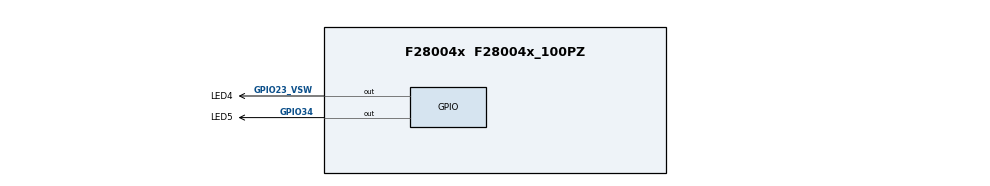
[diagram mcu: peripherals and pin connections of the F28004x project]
/**
 * @cliArgs --device "F28004x" --part "F28004x_100PZ" --package "F28004x_100PZ" --context "system" --product "C2000WARE@26.01.00.00"
 * @versions {"tool":"1.27.0+4565"}
 */

/**
 * Import the modules used in this configuration.
 */
const gpio  = scripting.addModule("/driverlib/gpio.js", {}, false);
const gpio1 = gpio.addInstance();
const gpio2 = gpio.addInstance();

/**
 * Write custom configuration values to the imported modules.
 */
gpio1.$name           = "LED4";
gpio1.direction       = "GPIO_DIR_MODE_OUT";
gpio1.gpioPin.$assign = "GPIO23_VSW";

gpio2.$name           = "LED5";
gpio2.direction       = "GPIO_DIR_MODE_OUT";
gpio2.gpioPin.$assign = "GPIO34";
